# PIC32MX250F128C register map
Vendor: Microchip
Registers are 32-bit, read-write, reset 0x0 unless marked. A register's access mark holds for its fields unless they carry their own. Addresses are absolute, and some are shared; only a register's first bit layout is shown; [hi:lo] are bit positions; {n}, {i} and the like mark numbered series; 'fields as' and 'values as' point back to an identical list.

## CONFIG — Configuration words, addresses in PhysicalSpace
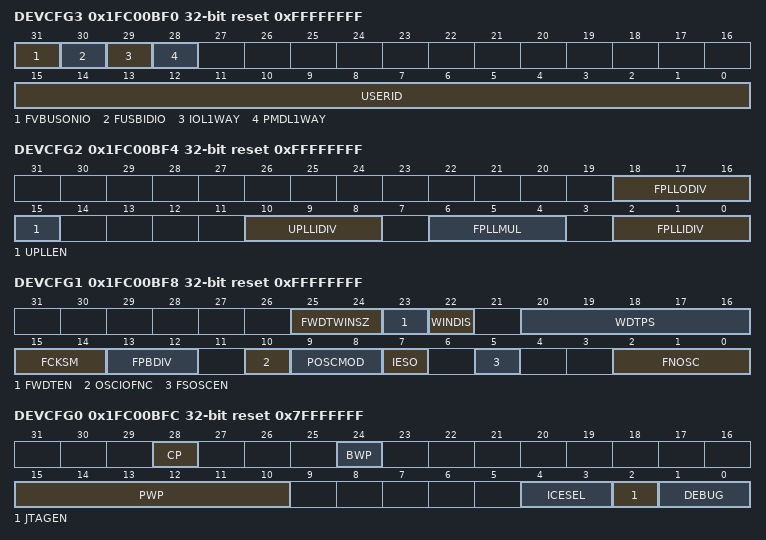
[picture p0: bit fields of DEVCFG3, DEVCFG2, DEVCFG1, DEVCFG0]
0x1FC00BF0 DEVCFG3 reset 0xFFFFFFFF
  [31] FVBUSONIO — USB VBUS ON Selection
    0=OFF (Controlled by Port Function); 1=ON (Controlled by USB Module)
  [30] FUSBIDIO — USB USID Selection
    0=OFF (Controlled by Port Function); 1=ON (Controlled by the USB Module)
  [29] IOL1WAY — Peripheral Pin Select Configuration
    1=ON (Allow only one reconfiguration); 0=OFF (Allow multiple reconfigurations)
  [28] PMDL1WAY — Peripheral Module Disable Configuration
    values as IOL1WAY
  [15:0] USERID
0x1FC00BF4 DEVCFG2 reset 0xFFFFFFFF
  [18:16] FPLLODIV — System PLL Output Clock Divider
    0=DIV_1 (PLL Divide by 1); 1=DIV_2 (PLL Divide by 2); 2=DIV_4 (PLL Divide by 4); 3=DIV_8 (PLL Divide by 8); 4=DIV_16 (PLL Divide by 16); 5=DIV_32 (PLL Divide by 32); 6=DIV_64 (PLL Divide by 64); 7=DIV_256 (PLL Divide by 256)
  [15] UPLLEN — USB PLL Enable
    0=ON (Enabled); 1=OFF (Disabled and Bypassed)
  [10:8] UPLLIDIV — USB PLL Input Divider
    {v}=DIV_{v+1} ({v+1}x Divider) (v=0..5); 6=DIV_10 (10x Divider); 7=DIV_12 (12x Divider)
  [6:4] FPLLMUL — PLL Multiplier
    {v}=MUL_{v+15} ({v+15}x Multiplier) (v=0..6); 7=MUL_24 (24x Multiplier)
  [2:0] FPLLIDIV — PLL Input Divider
    values as UPLLIDIV
0x1FC00BF8 DEVCFG1 reset 0xFFFFFFFF
  [25:24] FWDTWINSZ — Watchdog Timer Window Size
    0=WINSZ_75 (Window Size is 75%); 1=WINSZ_50 (Window Size is 50%); 2=WINSZ_37 (Window Size is 37.5%); 3=WINSZ_25 (Window Size is 25%)
  [23] FWDTEN — Watchdog Timer Enable
    0=OFF (WDT Disabled (SWDTEN Bit Controls)); 1=ON (WDT Enabled)
  [22] WINDIS — Watchdog Timer Window Enable
    0=ON (Watchdog Timer is in Window Mode); 1=OFF (Watchdog Timer is in Non-Window Mode)
  [20:16] WDTPS — Watchdog Timer Postscaler
    0=PS1 (1:1); 1=PS2 (1:2); 2=PS4 (1:4); 3=PS8 (1:8); 4=PS16 (1:16); 5=PS32 (1:32); 6=PS64 (1:64); 7=PS128 (1:128); 8=PS256 (1:256); 9=PS512 (1:512); 10=PS1024 (1:1024); 11=PS2048 (1:2048); 12=PS4096 (1:4096); 13=PS8192 (1:8192); 14=PS16384 (1:16384); 15=PS32768 (1:32768); 0b1x000=PS65536 (1:65536); 0b1x001=PS131072 (1:131072); 0b1x010=PS262144 (1:262144); 0b1x011=PS524288 (1:524288); 0b1x1xx=PS1048576 (1:1048576)
  [15:14] FCKSM — Clock Switching and Monitor Selection
    0=CSECME (Clock Switch Enable, FSCM Enabled); 1=CSECMD (Clock Switch Enable, FSCM Disabled); 3=CSDCMD (Clock Switch Disable, FSCM Disabled)
  [13:12] FPBDIV — Peripheral Clock Divisor
    0=DIV_1 (Pb_Clk is Sys_Clk/1); 1=DIV_2 (Pb_Clk is Sys_Clk/2); 2=DIV_4 (Pb_Clk is Sys_Clk/4); 3=DIV_8 (Pb_Clk is Sys_Clk/8)
  [10] OSCIOFNC — CLKO Output Signal Active on the OSCO Pin
    1=OFF (Disabled); 0=ON (Enabled)
  [9:8] POSCMOD — Primary Oscillator Configuration
    0=EC (External clock mode); 1=XT (XT osc mode); 2=HS (HS osc mode); 3=OFF (Primary osc disabled)
  [7] IESO — Internal/External Switch Over
    0=OFF (Disabled); 1=ON (Enabled)
  [5] FSOSCEN — Secondary Oscillator Enable
    0=OFF (Disabled); 1=ON (Enabled)
  [2:0] FNOSC — Oscillator Selection Bits
    0=FRC (Fast RC Osc (FRC)); 1=FRCPLL (Fast RC Osc with PLL); 2=PRI (Primary Osc (XT,HS,EC)); 3=PRIPLL (Primary Osc w/PLL (XT+,HS+,EC+PLL)); 4=SOSC (Low Power Secondary Osc (SOSC)); 5=LPRC (Low Power RC Osc (LPRC)); 6=FRCDIV16 (Fast RC Osc w/Div-by-16 (FRC/16)); 7=FRCDIV (Fast RC Osc w/Div-by-N (FRCDIV))
0x1FC00BFC DEVCFG0 reset 0x7FFFFFFF
  [28] CP — Code Protect
    0=ON (Protection Enabled); 1=OFF (Protection Disabled)
  [24] BWP — Boot Flash Write Protect bit
    0=ON (Protection Enabled); 1=OFF (Protection Disabled)
  [15:10] PWP — Program Flash Write Protect
    63=OFF (Disable); 62=PWP1K (First 1K); 61=PWP2K (First 2K); 60=PWP3K (First 3K); 59=PWP4K (First 4K); 58=PWP5K (First 5K); 57=PWP6K (First 6K); 56=PWP7K (First 7K); 55=PWP8K (First 8K); 54=PWP9K (First 9K); 53=PWP10K (First 10K); 52=PWP11K (First 11K); 51=PWP12K (First 12K); 50=PWP13K (First 13K); 49=PWP14K (First 14K); 48=PWP15K (First 15K); 47=PWP16K (First 16K); 46=PWP17K (First 17K); 45=PWP18K (First 18K); 44=PWP19K (First 19K); 43=PWP20K (First 20K); 42=PWP21K (First 21K); 41=PWP22K (First 22K); 40=PWP23K (First 23K); 39=PWP24K (First 24K); 38=PWP25K (First 25K); 37=PWP26K (First 26K); 36=PWP27K (First 27K); 35=PWP28K (First 28K); 34=PWP29K (First 29K); 33=PWP30K (First 30K); 32=PWP31K (First 31K); 31=PWP32K (First 32K)
  [4:3] ICESEL — ICE/ICD Comm Channel Select
    3=ICS_PGx1 (Communicate on PGEC1/PGED1); 2=ICS_PGx2 (Communicate on PGEC2/PGED2); 1=ICS_PGx3 (Communicate on PGEC3/PGED3); 0=ICS_PGx4 (Communicate on PGEC4/PGED4)
  [2] JTAGEN — JTAG Enable
    1=ON (JTAG Port Enabled); 0=OFF (JTAG Disabled)
  [1:0] DEBUG — Background Debugger Enable
    0=ON (Debugger is Enabled); 3=OFF (Debugger is Disabled)
